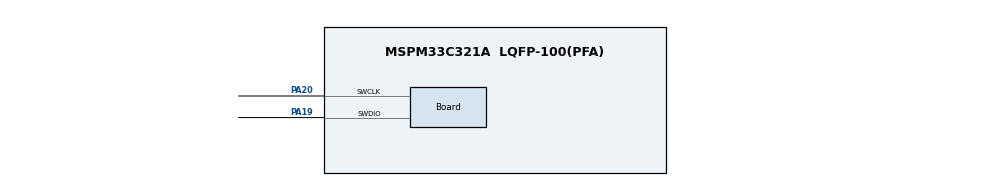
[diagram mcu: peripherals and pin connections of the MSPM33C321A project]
//@cliArgs --device "MSPM33C321A" --package "LQFP-100(PFA)" --part "Default"
//@v2CliArgs --device "MSPM33C321A" --package "LQFP-100(PFA)"
// @cliArgs --board /ti/boards/LP_MSPM33C321A --rtos nortos

/**
 * Import the modules used in this configuration.
 */
const HSADC         = scripting.addModule("/ti/driverlib/HSADC", {}, false);
const HSADC1        = HSADC.addInstance();
const TIMER         = scripting.addModule("/ti/driverlib/TIMER", {}, false);
const TIMER1        = TIMER.addInstance();
const ProjectConfig = scripting.addModule("/ti/project_config/ProjectConfig");

/**
 * Write custom configuration values to the imported modules.
 */
const Board                       = scripting.addModule("/ti/driverlib/Board", {}, false);
Board.peripheral.$assign          = "DEBUGSS";
Board.peripheral.swclkPin.$assign = "PA20";
Board.peripheral.swdioPin.$assign = "PA19";

HSADC1.$name                 = "HSADC0";
HSADC1.enabledSOCs           = ["ADC_SOC_NUMBER3"];
HSADC1.soc3Channel           = "ADC_CH_ADCIN_3";
HSADC1.enabledSEQs           = ["ADC_SEQ_NUMBER4"];
HSADC1.seqEndSOC             = "ADC_SOC_NUMBER3";
HSADC1.seq4StartSOC          = "ADC_SOC_NUMBER3";
HSADC1.seq4Enable            = true;
HSADC1.seq4TriggerSel        = "ADC_TRIGGER_GEN_SUB_0";
HSADC1.seq4SampleWindow      = 16;
HSADC1.enabledInts           = ["ADC_INT_NUMBER_1"];
HSADC1.interrupt1SOCSource   = "ADC_SOC_NUMBER3";
HSADC1.enableInterrupt1      = true;
HSADC1.ADCsubscriber1Channel = 1;
HSADC1.peripheral.$assign    = "ADC0";

const SYSCTL              = scripting.addModule("/ti/driverlib/SYSCTL", {}, false);
SYSCTL.peripheral.$assign = "SYSCTL";

TIMER1.$name                       = "TIMER_0";
TIMER1.event1PublisherChannel      = 1;
TIMER1.event1ControllerInterruptEn = ["ZERO_EVENT"];
TIMER1.timerClkPrescale            = 256;
TIMER1.timerPeriod                 = "1.125 s";
TIMER1.timerClkDiv                 = 4;
TIMER1.peripheral.$assign          = "TIMA0_0";

ProjectConfig.genLinker          = true;
ProjectConfig.genStartup         = true;
ProjectConfig.genOpts            = true;
ProjectConfig.genLibs            = true;
ProjectConfig.migrationCondition = true;
